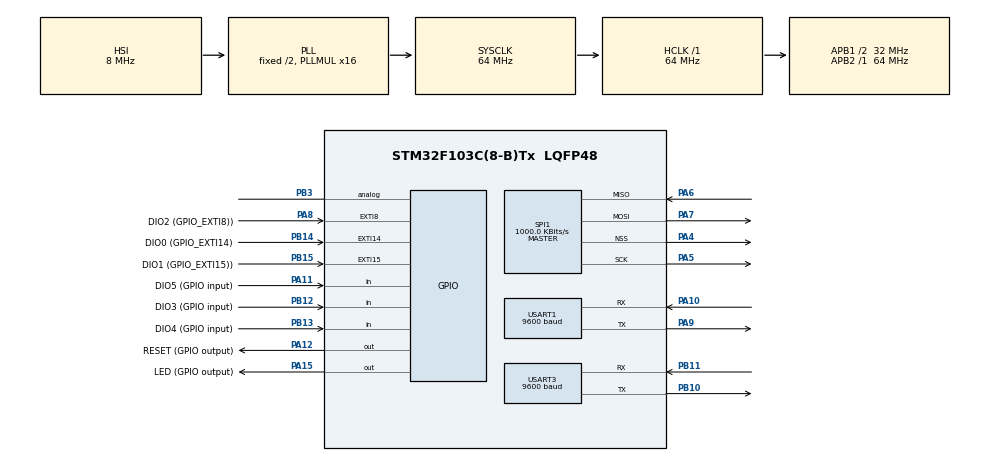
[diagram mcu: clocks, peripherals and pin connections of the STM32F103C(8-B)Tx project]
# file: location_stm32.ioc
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Mcu.Family=STM32F1
Mcu.Name=STM32F103C(8-B)Tx
Mcu.Package=LQFP48
NVIC.EXTI15_10_IRQn=true\:0\:0\:false\:false\:true\:true\:true
NVIC.EXTI9_5_IRQn=true\:0\:0\:false\:false\:true\:true\:true
NVIC.PriorityGroup=NVIC_PRIORITYGROUP_4
NVIC.TIM4_IRQn=true\:0\:0\:false\:false\:true\:true\:true
PA10.Mode=Asynchronous
PA10.Signal=USART1_RX
PA11.GPIO_Label=DIO5 (GPIO input)
PA11.Signal=GPIO_Input
PA12.GPIO_Label=RESET (GPIO output)
PA12.Signal=GPIO_Output
PA13.Mode=Serial_Wire
PA13.Signal=SYS_JTMS-SWDIO
PA14.Mode=Serial_Wire
PA14.Signal=SYS_JTCK-SWCLK
PA15.GPIO_Label=LED (GPIO output)
PA15.Signal=GPIO_Output
PA4.Mode=NSS_Signal_Hard_Output
PA4.Signal=SPI1_NSS
PA5.Mode=Full_Duplex_Master
PA5.Signal=SPI1_SCK
PA6.Mode=Full_Duplex_Master
PA6.Signal=SPI1_MISO
PA7.Mode=Full_Duplex_Master
PA7.Signal=SPI1_MOSI
PA8.GPIO_Label=DIO2 (GPIO_EXTI8))
PA8.Signal=GPXTI8
PA9.Mode=Asynchronous
PA9.Signal=USART1_TX
PB10.Mode=Asynchronous
PB10.Signal=USART3_TX
PB11.Mode=Asynchronous
PB11.Signal=USART3_RX
PB12.GPIO_Label=DIO3 (GPIO input)
PB12.Signal=GPIO_Input
PB13.GPIO_Label=DIO4 (GPIO input)
PB13.Signal=GPIO_Input
PB14.GPIO_Label=DIO0 (GPIO_EXTI14)
PB14.Signal=GPXTI14
PB15.GPIO_Label=DIO1 (GPIO_EXTI15))
PB15.Signal=GPXTI15
PB3.Signal=GPIO_Analog
ProjectManager.HeapSize=0x200
ProjectManager.StackSize=0x400
ProjectManager.TargetToolchain=Makefile
RCC.AHBFreq_Value=64000000
RCC.APB1CLKDivider=RCC_HCLK_DIV2
RCC.APB1Freq_Value=32000000
RCC.APB1TimFreq_Value=64000000
RCC.APB2Freq_Value=64000000
RCC.APB2TimFreq_Value=64000000
RCC.HCLKFreq_Value=64000000
RCC.PLLMUL=RCC_PLL_MUL16
RCC.SYSCLKFreq_VALUE=64000000
RCC.SYSCLKSource=RCC_SYSCLKSOURCE_PLLCLK
RCC.USBFreq_Value=64000000
SPI1.BaudRatePrescaler=SPI_BAUDRATEPRESCALER_64
SPI1.CalculateBaudRate=1000.0 KBits/s
SPI1.Direction=SPI_DIRECTION_2LINES
SPI1.Mode=SPI_MODE_MASTER
SPI1.VirtualNSS=VM_NSSHARD
SPI1.VirtualType=VM_MASTER
TIM4.Channel-Output\ Compare1\ No\ Output=TIM_CHANNEL_1
TIM4.Period=65535-1
TIM4.Prescaler=2000-1
USART1.BaudRate=9600
USART1.VirtualMode=VM_ASYNC
USART3.BaudRate=9600
USART3.VirtualMode=VM_ASYNC
VP_TIM4_VS_no_output1.Mode=Output Compare1 No Output
board=custom

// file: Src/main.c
/* USER CODE BEGIN Header */
/**
  ******************************************************************************
  * @file           : main.c
  * @brief          : Main program body
  ******************************************************************************
  * @attention
  *
  * <h2><center>&copy; Copyright (c) 2020 STMicroelectronics.
  * All rights reserved.</center></h2>
  *
  * This software component is licensed by ST under BSD 3-Clause license,
  * the "License"; You may not use this file except in compliance with the
  * License. You may obtain a copy of the License at:
  *                        opensource.org/licenses/BSD-3-Clause
  *
  ******************************************************************************
  */
/* USER CODE END Header */

#include "main.h"

SPI_HandleTypeDef hspi1;

TIM_HandleTypeDef htim4;

UART_HandleTypeDef huart1;
UART_HandleTypeDef huart3;

void SystemClock_Config(void);
static void MX_GPIO_Init(void);
static void MX_USART1_UART_Init(void);
static void MX_USART3_UART_Init(void);
static void MX_SPI1_Init(void);
static void MX_TIM4_Init(void);

int main(void)
{

  /* MCU Configuration--------------------------------------------------------*/

  /* Reset of all peripherals, Initializes the Flash interface and the Systick. */
  HAL_Init();

  /* Configure the system clock */
  SystemClock_Config();

  /* Initialize all configured peripherals */
  MX_GPIO_Init();
  MX_USART1_UART_Init();
  MX_USART3_UART_Init();
  MX_SPI1_Init();
  MX_TIM4_Init();
  /* USER CODE BEGIN 2 */

  uint8_t cnt = 0;

  /* USER CODE END 2 */

  /* Infinite loop */
  while (1)
  {

  }
}

void SystemClock_Config(void)
{
  RCC_OscInitTypeDef RCC_OscInitStruct = {0};
  RCC_ClkInitTypeDef RCC_ClkInitStruct = {0};

  /** Initializes the CPU, AHB and APB busses clocks
  */
  RCC_OscInitStruct.OscillatorType = RCC_OSCILLATORTYPE_HSI;
  RCC_OscInitStruct.HSIState = RCC_HSI_ON;
  RCC_OscInitStruct.HSICalibrationValue = RCC_HSICALIBRATION_DEFAULT;
  RCC_OscInitStruct.PLL.PLLState = RCC_PLL_ON;
  RCC_OscInitStruct.PLL.PLLSource = RCC_PLLSOURCE_HSI_DIV2;
  RCC_OscInitStruct.PLL.PLLMUL = RCC_PLL_MUL16;
  if (HAL_RCC_OscConfig(&RCC_OscInitStruct) != HAL_OK)
  {
    Error_Handler();
  }
  /** Initializes the CPU, AHB and APB busses clocks
  */
  RCC_ClkInitStruct.ClockType = RCC_CLOCKTYPE_HCLK|RCC_CLOCKTYPE_SYSCLK
                              |RCC_CLOCKTYPE_PCLK1|RCC_CLOCKTYPE_PCLK2;
  RCC_ClkInitStruct.SYSCLKSource = RCC_SYSCLKSOURCE_PLLCLK;
  RCC_ClkInitStruct.AHBCLKDivider = RCC_SYSCLK_DIV1;
  RCC_ClkInitStruct.APB1CLKDivider = RCC_HCLK_DIV2;
  RCC_ClkInitStruct.APB2CLKDivider = RCC_HCLK_DIV1;

  if (HAL_RCC_ClockConfig(&RCC_ClkInitStruct, FLASH_LATENCY_2) != HAL_OK)
  {
    Error_Handler();
  }
}

static void MX_SPI1_Init(void)
{

  /* SPI1 parameter configuration*/
  hspi1.Instance = SPI1;
  hspi1.Init.Mode = SPI_MODE_MASTER;
  hspi1.Init.Direction = SPI_DIRECTION_2LINES;
  hspi1.Init.DataSize = SPI_DATASIZE_8BIT;
  hspi1.Init.CLKPolarity = SPI_POLARITY_LOW;
  hspi1.Init.CLKPhase = SPI_PHASE_1EDGE;
  hspi1.Init.NSS = SPI_NSS_HARD_OUTPUT;
  hspi1.Init.BaudRatePrescaler = SPI_BAUDRATEPRESCALER_64;
  hspi1.Init.FirstBit = SPI_FIRSTBIT_MSB;
  hspi1.Init.TIMode = SPI_TIMODE_DISABLE;
  hspi1.Init.CRCCalculation = SPI_CRCCALCULATION_DISABLE;
  hspi1.Init.CRCPolynomial = 10;
  if (HAL_SPI_Init(&hspi1) != HAL_OK)
  {
    Error_Handler();
  }

}

static void MX_TIM4_Init(void)
{

  TIM_MasterConfigTypeDef sMasterConfig = {0};
  TIM_OC_InitTypeDef sConfigOC = {0};

  htim4.Instance = TIM4;
  htim4.Init.Prescaler = 2000-1;
  htim4.Init.CounterMode = TIM_COUNTERMODE_UP;
  htim4.Init.Period = 65535-1;
  htim4.Init.ClockDivision = TIM_CLOCKDIVISION_DIV1;
  htim4.Init.AutoReloadPreload = TIM_AUTORELOAD_PRELOAD_DISABLE;
  if (HAL_TIM_OC_Init(&htim4) != HAL_OK)
  {
    Error_Handler();
  }
  sMasterConfig.MasterOutputTrigger = TIM_TRGO_RESET;
  sMasterConfig.MasterSlaveMode = TIM_MASTERSLAVEMODE_DISABLE;
  if (HAL_TIMEx_MasterConfigSynchronization(&htim4, &sMasterConfig) != HAL_OK)
  {
    Error_Handler();
  }
  sConfigOC.OCMode = TIM_OCMODE_TIMING;
  sConfigOC.Pulse = 0;
  sConfigOC.OCPolarity = TIM_OCPOLARITY_HIGH;
  sConfigOC.OCFastMode = TIM_OCFAST_DISABLE;
  if (HAL_TIM_OC_ConfigChannel(&htim4, &sConfigOC, TIM_CHANNEL_1) != HAL_OK)
  {
    Error_Handler();
  }

}

static void MX_USART1_UART_Init(void)
{

  huart1.Instance = USART1;
  huart1.Init.BaudRate = 9600;
  huart1.Init.WordLength = UART_WORDLENGTH_8B;
  huart1.Init.StopBits = UART_STOPBITS_1;
  huart1.Init.Parity = UART_PARITY_NONE;
  huart1.Init.Mode = UART_MODE_TX_RX;
  huart1.Init.HwFlowCtl = UART_HWCONTROL_NONE;
  huart1.Init.OverSampling = UART_OVERSAMPLING_16;
  if (HAL_UART_Init(&huart1) != HAL_OK)
  {
    Error_Handler();
  }

}

static void MX_USART3_UART_Init(void)
{

  huart3.Instance = USART3;
  huart3.Init.BaudRate = 9600;
  huart3.Init.WordLength = UART_WORDLENGTH_8B;
  huart3.Init.StopBits = UART_STOPBITS_1;
  huart3.Init.Parity = UART_PARITY_NONE;
  huart3.Init.Mode = UART_MODE_TX_RX;
  huart3.Init.HwFlowCtl = UART_HWCONTROL_NONE;
  huart3.Init.OverSampling = UART_OVERSAMPLING_16;
  if (HAL_UART_Init(&huart3) != HAL_OK)
  {
    Error_Handler();
  }

}

static void MX_GPIO_Init(void)
{
  GPIO_InitTypeDef GPIO_InitStruct = {0};

  /* GPIO Ports Clock Enable */
  __HAL_RCC_GPIOA_CLK_ENABLE();
  __HAL_RCC_GPIOB_CLK_ENABLE();

  /*Configure GPIO pin Output Level */
  HAL_GPIO_WritePin(GPIOA, RESET_Pin|LED_Pin, GPIO_PIN_RESET);

  /*Configure GPIO pins : DIO3_Pin DIO4_Pin */
  GPIO_InitStruct.Pin = DIO3_Pin|DIO4_Pin;
  GPIO_InitStruct.Mode = GPIO_MODE_INPUT;
  GPIO_InitStruct.Pull = GPIO_NOPULL;
  HAL_GPIO_Init(GPIOB, &GPIO_InitStruct);

  /*Configure GPIO pins : DIO0_Pin DIO1_Pin */
  GPIO_InitStruct.Pin = DIO0_Pin|DIO1_Pin;
  GPIO_InitStruct.Mode = GPIO_MODE_IT_RISING;
  GPIO_InitStruct.Pull = GPIO_NOPULL;
  HAL_GPIO_Init(GPIOB, &GPIO_InitStruct);

  /*Configure GPIO pin : DIO2_Pin */
  GPIO_InitStruct.Pin = DIO2_Pin;
  GPIO_InitStruct.Mode = GPIO_MODE_IT_RISING;
  GPIO_InitStruct.Pull = GPIO_NOPULL;
  HAL_GPIO_Init(DIO2_GPIO_Port, &GPIO_InitStruct);

  /*Configure GPIO pin : DIO5_Pin */
  GPIO_InitStruct.Pin = DIO5_Pin;
  GPIO_InitStruct.Mode = GPIO_MODE_INPUT;
  GPIO_InitStruct.Pull = GPIO_NOPULL;
  HAL_GPIO_Init(DIO5_GPIO_Port, &GPIO_InitStruct);

  /*Configure GPIO pins : RESET_Pin LED_Pin */
  GPIO_InitStruct.Pin = RESET_Pin|LED_Pin;
  GPIO_InitStruct.Mode = GPIO_MODE_OUTPUT_PP;
  GPIO_InitStruct.Pull = GPIO_NOPULL;
  GPIO_InitStruct.Speed = GPIO_SPEED_FREQ_LOW;
  HAL_GPIO_Init(GPIOA, &GPIO_InitStruct);

  /*Configure GPIO pin : PB3 */
  GPIO_InitStruct.Pin = GPIO_PIN_3;
  GPIO_InitStruct.Mode = GPIO_MODE_ANALOG;
  HAL_GPIO_Init(GPIOB, &GPIO_InitStruct);

  /* EXTI interrupt init*/
  HAL_NVIC_SetPriority(EXTI9_5_IRQn, 0, 0);
  HAL_NVIC_EnableIRQ(EXTI9_5_IRQn);

  HAL_NVIC_SetPriority(EXTI15_10_IRQn, 0, 0);
  HAL_NVIC_EnableIRQ(EXTI15_10_IRQn);

}

void Error_Handler(void)
{
}

/************************ (C) COPYRIGHT STMicroelectronics *****END OF FILE****/
